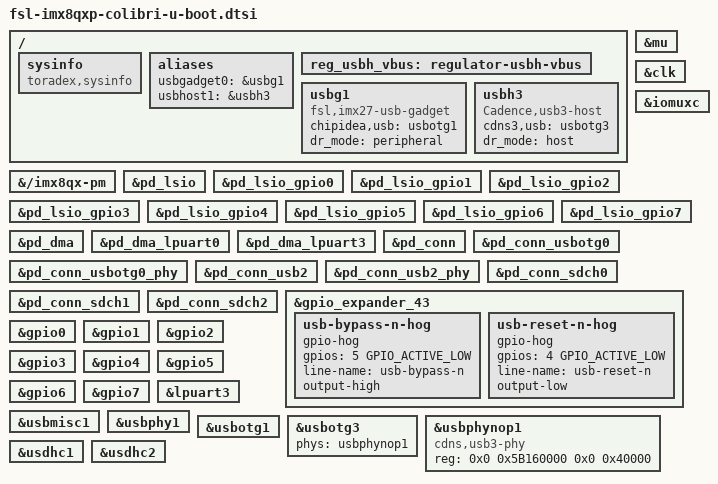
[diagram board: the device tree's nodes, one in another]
// SPDX-License-Identifier: GPL-2.0+ OR X11
/*
 * Copyright 2019 Toradex AG
 */

/ {
	sysinfo {
		compatible = "toradex,sysinfo";
	};

	aliases {
		usbgadget0 = &usbg1;
		usbhost1 = &usbh3;
	};

	reg_usbh_vbus: regulator-usbh-vbus {
		status = "okay";
		bootph-some-ram;
	};

	usbg1: usbg1 {
		compatible = "fsl,imx27-usb-gadget";
		chipidea,usb = <&usbotg1>;
		dr_mode = "peripheral";
		status = "okay";
		bootph-some-ram;
	};

	usbh3: usbh3 {
		compatible = "Cadence,usb3-host";
		cdns3,usb = <&usbotg3>;
		dr_mode = "host";
		status = "okay";
		bootph-some-ram;
	};
};

&{/imx8qx-pm} {

	bootph-some-ram;
};

&mu {
	bootph-some-ram;
};

&clk {
	bootph-some-ram;
};

&iomuxc {
	bootph-some-ram;
};

&pd_lsio {
	bootph-some-ram;
};

&pd_lsio_gpio0 {
	bootph-some-ram;
};

&pd_lsio_gpio1 {
	bootph-some-ram;
};

&pd_lsio_gpio2 {
	bootph-some-ram;
};

&pd_lsio_gpio3 {
	bootph-some-ram;
};

&pd_lsio_gpio4 {
	bootph-some-ram;
};

&pd_lsio_gpio5 {
	bootph-some-ram;
};

&pd_lsio_gpio6 {
	bootph-some-ram;
};

&pd_lsio_gpio7 {
	bootph-some-ram;
};

&pd_dma {
	bootph-some-ram;
};

&pd_dma_lpuart0 {
	bootph-some-ram;
};

&pd_dma_lpuart3 {
	bootph-some-ram;
};

&pd_conn {
	bootph-some-ram;
};

&pd_conn_usbotg0 {
	bootph-some-ram;
};

&pd_conn_usbotg0_phy {
	bootph-some-ram;
};

&pd_conn_usb2 {
	bootph-some-ram;
};

&pd_conn_usb2_phy {
	bootph-some-ram;
};

&pd_conn_sdch0 {
	bootph-some-ram;
};

&pd_conn_sdch1 {
	bootph-some-ram;
};

&pd_conn_sdch2 {
	bootph-some-ram;
};

&gpio_expander_43 {
	usb-bypass-n-hog {
		gpio-hog;
		gpios = <5 GPIO_ACTIVE_LOW>;
		line-name = "usb-bypass-n";
		output-high;
	};
	usb-reset-n-hog {
		gpio-hog;
		gpios = <4 GPIO_ACTIVE_LOW>;
		line-name = "usb-reset-n";
		output-low;
	};
};

&gpio0 {
	bootph-some-ram;
};

&gpio1 {
	bootph-some-ram;
};

&gpio2 {
	bootph-some-ram;
};

&gpio3 {
	bootph-some-ram;
};

&gpio4 {
	bootph-some-ram;
};

&gpio5 {
	bootph-some-ram;
};

&gpio6 {
	bootph-some-ram;
};

&gpio7 {
	bootph-some-ram;
};

&lpuart3 {
	bootph-some-ram;
};

&usbmisc1 {
	bootph-some-ram;
};

&usbphy1 {
	bootph-some-ram;
};

&usbotg1 {
	bootph-some-ram;
};

&usbotg3 {
	phys = <&usbphynop1>;
	bootph-some-ram;
};

&usbphynop1 {
	compatible = "cdns,usb3-phy";
	#phy-cells = <0>;
	reg = <0x0 0x5B160000 0x0 0x40000>;
	bootph-some-ram;
};

&usdhc1 {
	bootph-some-ram;
};

&usdhc2 {
	bootph-some-ram;
};
